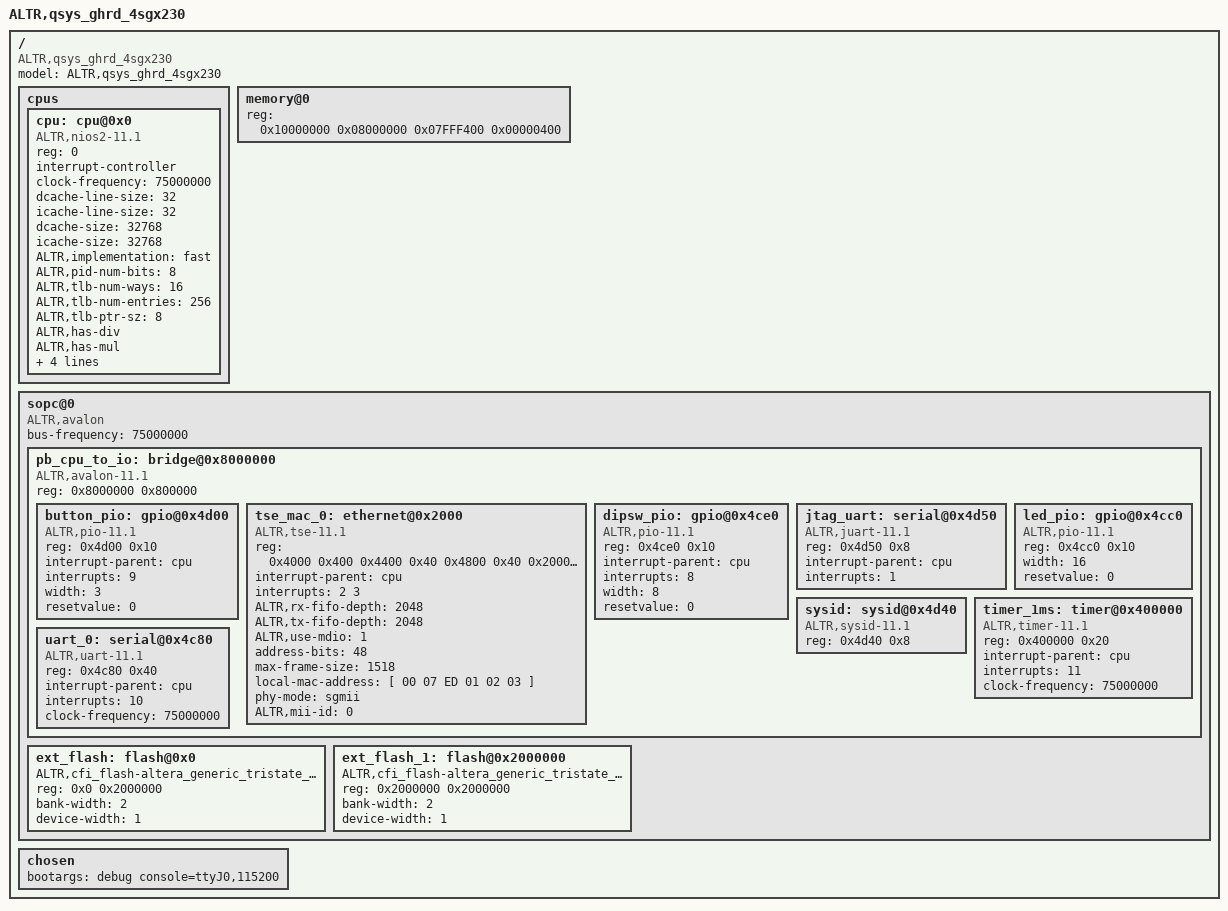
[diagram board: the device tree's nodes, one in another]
/*
 * This devicetree is generated by sopc2dts
 * Sopc2dts is written by Walter Goossens <waltergoossens@home.nl>
 * in cooperation with the nios2 community <Nios2-dev@sopc.et.ntust.edu.tw>
 */
/dts-v1/;
/ {
	model = "ALTR,qsys_ghrd_4sgx230";
	compatible = "ALTR,qsys_ghrd_4sgx230";
	#address-cells = <1>;
	#size-cells = <1>;
	cpus {
		#address-cells = <1>;
		#size-cells = <0>;
		cpu: cpu@0x0 {
			device_type = "cpu";
			compatible = "ALTR,nios2-11.1";
			reg = <0>;
			interrupt-controller;
			#interrupt-cells = <1>;
			clock-frequency = <75000000>;	//embeddedsw.CMacro.CPU_FREQ type NUMBER
			dcache-line-size = <32>;	//embeddedsw.CMacro.DCACHE_LINE_SIZE type NUMBER
			icache-line-size = <32>;	//embeddedsw.CMacro.ICACHE_LINE_SIZE type NUMBER
			dcache-size = <32768>;	//embeddedsw.CMacro.DCACHE_SIZE type NUMBER
			icache-size = <32768>;	//embeddedsw.CMacro.ICACHE_SIZE type NUMBER
			ALTR,implementation = "fast";	//embeddedsw.CMacro.CPU_IMPLEMENTATION type STRING
			ALTR,pid-num-bits = <8>;	//embeddedsw.CMacro.PROCESS_ID_NUM_BITS type NUMBER
			ALTR,tlb-num-ways = <16>;	//embeddedsw.CMacro.TLB_NUM_WAYS type NUMBER
			ALTR,tlb-num-entries = <256>;	//embeddedsw.CMacro.TLB_NUM_ENTRIES type NUMBER
			ALTR,tlb-ptr-sz = <8>;	//embeddedsw.CMacro.TLB_PTR_SZ type NUMBER
			ALTR,has-div;	//embeddedsw.CMacro.HARDWARE_DIVIDE_PRESENT type NUMBER
			ALTR,has-mul;	//embeddedsw.CMacro.HARDWARE_MULTIPLY_PRESENT type NUMBER
			ALTR,has-mulx;	//embeddedsw.CMacro.HARDWARE_MULX_PRESENT type NUMBER
			ALTR,reset-addr = <0xc2800000>;	//embeddedsw.CMacro.RESET_ADDR type NUMBER
			ALTR,fast-tlb-miss-addr = <0xc7fff400>;	//embeddedsw.CMacro.FAST_TLB_MISS_EXCEPTION_ADDR type NUMBER
			ALTR,exception-addr = <0xd0000020>;	//embeddedsw.CMacro.EXCEPTION_ADDR type NUMBER
		};
	};
	memory@0 {
		device_type = "memory";
		reg = <0x10000000 0x08000000
			0x07FFF400 0x00000400>;
	};
	sopc@0 {
		ranges ;
		#address-cells = <1>;
		#size-cells = <1>;
		device_type = "soc";
		compatible = "ALTR,avalon","simple-bus";
		bus-frequency = < 75000000 >;
		pb_cpu_to_io: bridge@0x8000000 {
			compatible = "ALTR,avalon-11.1","simple-bus";
			reg = < 0x8000000 0x800000>;
			#address-cells = <1>;
			#size-cells = <1>;
			ranges = <0x00004D00 0x08004D00 0x00000010
				0x00002000 0x08002000 0x00002000
				0x00004CE0 0x08004CE0 0x00000010
				0x00004D50 0x08004D50 0x00000008
				0x00004CC0 0x08004CC0 0x00000010
				0x00004400 0x08004400 0x00000040
				0x00004800 0x08004800 0x00000040
				0x00004D40 0x08004D40 0x00000008
				0x00400000 0x08400000 0x00000020
				0x00004000 0x08004000 0x00000400
				0x00004C80 0x08004C80 0x00000040>;

			button_pio: gpio@0x4d00 {
				compatible = "ALTR,pio-11.1","ALTR,pio-1.0";
				reg = < 0x4d00 0x10>;
				interrupt-parent = < &cpu >;
				interrupts = < 9 >;
				width = <3>;	//width type NUMBER
				resetvalue = <0>;	//resetValue type NUMBER
			}; //end gpio (button_pio)

			tse_mac_0: ethernet@0x2000 {
				compatible = "ALTR,tse-11.1","ALTR,tse-1.0";
				reg = < 0x4000 0x400 0x4400 0x40 0x4800 0x40 0x2000 0x2000>;
				interrupt-parent = < &cpu >;
				interrupts = < 2 3 >;
				ALTR,rx-fifo-depth = <2048>;	//embeddedsw.CMacro.RECEIVE_FIFO_DEPTH type NUMBER
				ALTR,tx-fifo-depth = <2048>;	//embeddedsw.CMacro.TRANSMIT_FIFO_DEPTH type NUMBER
				ALTR,use-mdio = <1>;	//embeddedsw.CMacro.USE_MDIO type NUMBER
				address-bits = <48>;
				max-frame-size = <1518>;
				local-mac-address = [ 00 07 ED 01 02 03 ];
				phy-mode = "sgmii";
				ALTR,mii-id = <0>;
			}; //end ethernet (tse_mac_0)

			dipsw_pio: gpio@0x4ce0 {
				compatible = "ALTR,pio-11.1","ALTR,pio-1.0";
				reg = < 0x4ce0 0x10>;
				interrupt-parent = < &cpu >;
				interrupts = < 8 >;
				width = <8>;	//width type NUMBER
				resetvalue = <0>;	//resetValue type NUMBER
			}; //end gpio (dipsw_pio)

			jtag_uart: serial@0x4d50 {
				compatible = "ALTR,juart-11.1","ALTR,juart-1.0";
				reg = < 0x4d50 0x8>;
				interrupt-parent = < &cpu >;
				interrupts = < 1 >;
			}; //end serial (jtag_uart)

			led_pio: gpio@0x4cc0 {
				compatible = "ALTR,pio-11.1","ALTR,pio-1.0";
				reg = < 0x4cc0 0x10>;
				width = <16>;	//width type NUMBER
				resetvalue = <0>;	//resetValue type NUMBER
			}; //end gpio (led_pio)

			sysid: sysid@0x4d40 {
				compatible = "ALTR,sysid-11.1","ALTR,sysid-1.0";
				reg = < 0x4d40 0x8>;
			}; //end sysid (sysid)

			timer_1ms: timer@0x400000 {
				compatible = "ALTR,timer-11.1","ALTR,timer-1.0";
				reg = < 0x400000 0x20>;
				interrupt-parent = < &cpu >;
				interrupts = < 11 >;
				clock-frequency = <75000000>;
			}; //end timer (timer_1ms)

			uart_0: serial@0x4c80 {
				compatible = "ALTR,uart-11.1","ALTR,uart-1.0";
				reg = < 0x4c80 0x40>;
				interrupt-parent = < &cpu >;
				interrupts = < 10 >;
				clock-frequency = <75000000>;
			}; //end serial (uart_0)

		}; //end bridge (pb_cpu_to_io)

		ext_flash: flash@0x0 {
			compatible = "ALTR,cfi_flash-altera_generic_tristate_controller","cfi-flash";
			reg = < 0x0 0x2000000>;
			bank-width = <2>;
			device-width = <1>;
		}; //end flash (ext_flash)

		ext_flash_1: flash@0x2000000 {
			compatible = "ALTR,cfi_flash-altera_generic_tristate_controller","cfi-flash";
			reg = < 0x2000000 0x2000000>;
			bank-width = <2>;
			device-width = <1>;
		}; //end flash (ext_flash_1)

	}; //sopc
	chosen {
		bootargs = "debug console=ttyJ0,115200";
	};
};
